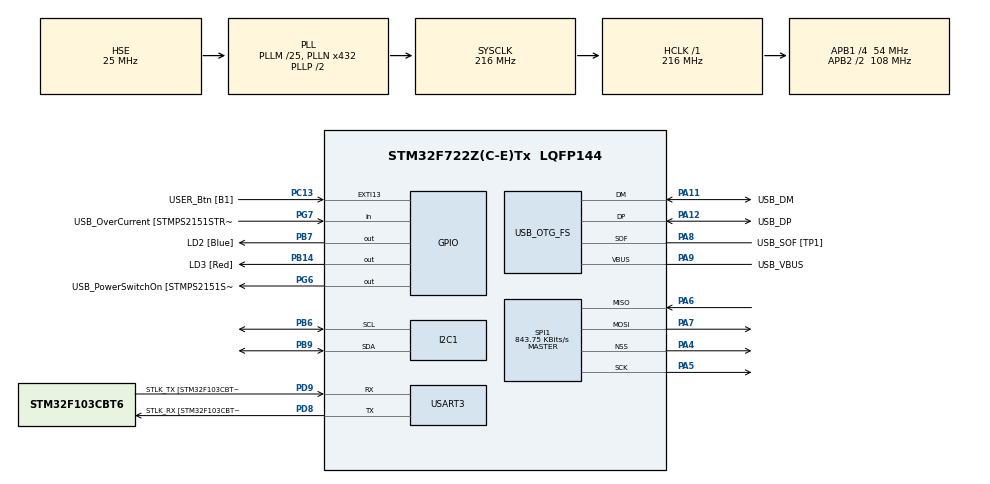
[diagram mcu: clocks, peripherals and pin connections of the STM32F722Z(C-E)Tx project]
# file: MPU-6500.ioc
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Dma.I2C1_RX.1.Direction=DMA_PERIPH_TO_MEMORY
Dma.I2C1_RX.1.FIFOMode=DMA_FIFOMODE_DISABLE
Dma.I2C1_RX.1.Instance=DMA1_Stream0
Dma.I2C1_RX.1.MemDataAlignment=DMA_MDATAALIGN_BYTE
Dma.I2C1_RX.1.MemInc=DMA_MINC_ENABLE
Dma.I2C1_RX.1.Mode=DMA_CIRCULAR
Dma.I2C1_RX.1.PeriphDataAlignment=DMA_PDATAALIGN_BYTE
Dma.I2C1_RX.1.PeriphInc=DMA_PINC_DISABLE
Dma.I2C1_RX.1.Priority=DMA_PRIORITY_MEDIUM
Dma.I2C1_TX.0.Direction=DMA_MEMORY_TO_PERIPH
Dma.I2C1_TX.0.FIFOMode=DMA_FIFOMODE_DISABLE
Dma.I2C1_TX.0.Instance=DMA1_Stream6
Dma.I2C1_TX.0.MemDataAlignment=DMA_MDATAALIGN_BYTE
Dma.I2C1_TX.0.MemInc=DMA_MINC_ENABLE
Dma.I2C1_TX.0.Mode=DMA_CIRCULAR
Dma.I2C1_TX.0.PeriphDataAlignment=DMA_PDATAALIGN_BYTE
Dma.I2C1_TX.0.PeriphInc=DMA_PINC_DISABLE
Dma.I2C1_TX.0.Priority=DMA_PRIORITY_MEDIUM
Dma.Request0=I2C1_TX
Dma.Request1=I2C1_RX
Dma.Request2=SPI1_RX
Dma.Request3=SPI1_TX
Dma.SPI1_RX.2.Direction=DMA_PERIPH_TO_MEMORY
Dma.SPI1_RX.2.FIFOMode=DMA_FIFOMODE_DISABLE
Dma.SPI1_RX.2.Instance=DMA2_Stream0
Dma.SPI1_RX.2.MemDataAlignment=DMA_MDATAALIGN_BYTE
Dma.SPI1_RX.2.MemInc=DMA_MINC_ENABLE
Dma.SPI1_RX.2.Mode=DMA_NORMAL
Dma.SPI1_RX.2.PeriphDataAlignment=DMA_PDATAALIGN_BYTE
Dma.SPI1_RX.2.PeriphInc=DMA_PINC_DISABLE
Dma.SPI1_RX.2.Priority=DMA_PRIORITY_HIGH
Dma.SPI1_TX.3.Direction=DMA_MEMORY_TO_PERIPH
Dma.SPI1_TX.3.FIFOMode=DMA_FIFOMODE_DISABLE
Dma.SPI1_TX.3.Instance=DMA2_Stream3
Dma.SPI1_TX.3.MemDataAlignment=DMA_MDATAALIGN_BYTE
Dma.SPI1_TX.3.MemInc=DMA_MINC_ENABLE
Dma.SPI1_TX.3.Mode=DMA_NORMAL
Dma.SPI1_TX.3.PeriphDataAlignment=DMA_PDATAALIGN_BYTE
Dma.SPI1_TX.3.PeriphInc=DMA_PINC_DISABLE
Dma.SPI1_TX.3.Priority=DMA_PRIORITY_HIGH
I2C1.Timing=0x20404768
Mcu.Family=STM32F7
Mcu.Name=STM32F722Z(C-E)Tx
Mcu.Package=LQFP144
NVIC.DMA1_Stream0_IRQn=true\:0\:0\:false\:false\:true\:false\:true
NVIC.DMA1_Stream6_IRQn=true\:0\:0\:false\:false\:true\:false\:true
NVIC.DMA2_Stream0_IRQn=true\:0\:0\:false\:false\:true\:false\:true
NVIC.DMA2_Stream3_IRQn=true\:0\:0\:false\:false\:true\:false\:true
NVIC.PriorityGroup=NVIC_PRIORITYGROUP_4
NVIC.SPI1_IRQn=true\:0\:0\:false\:false\:true\:true\:true
PA10.GPIO_Label=USB_ID
PA10.Signal=USB_OTG_FS_ID
PA11.GPIO_Label=USB_DM
PA11.Mode=Device_Only
PA11.Signal=USB_OTG_FS_DM
PA12.GPIO_Label=USB_DP
PA12.Mode=Device_Only
PA12.Signal=USB_OTG_FS_DP
PA13.GPIO_Label=TMS
PA13.Mode=Serial_Wire
PA13.Signal=SYS_JTMS-SWDIO
PA14.GPIO_Label=TCK
PA14.Mode=Serial_Wire
PA14.Signal=SYS_JTCK-SWCLK
PA4.Mode=NSS_Signal_Hard_Output
PA4.Signal=SPI1_NSS
PA5.Mode=Full_Duplex_Master
PA5.Signal=SPI1_SCK
PA6.Mode=Full_Duplex_Master
PA6.Signal=SPI1_MISO
PA7.Mode=Full_Duplex_Master
PA7.Signal=SPI1_MOSI
PA8.GPIO_Label=USB_SOF [TP1]
PA8.Mode=Activate_SOF_FS
PA8.Signal=USB_OTG_FS_SOF
PA9.GPIO_Label=USB_VBUS
PA9.Mode=Activate_VBUS
PA9.Signal=USB_OTG_FS_VBUS
PB14.GPIO_Label=LD3 [Red]
PB14.Signal=GPIO_Output
PB3.GPIO_Label=SWO
PB3.Signal=SYS_JTDO-SWO
PB6.Mode=I2C
PB6.Signal=I2C1_SCL
PB7.GPIO_Label=LD2 [Blue]
PB7.Signal=GPIO_Output
PB9.Mode=I2C
PB9.Signal=I2C1_SDA
PC13.GPIO_Label=USER_Btn [B1]
PC13.Signal=GPXTI13
PC14-OSC32_IN.Mode=LSE-External-Oscillator
PC14-OSC32_IN.Signal=RCC_OSC32_IN
PC15-OSC32_OUT.Mode=LSE-External-Oscillator
PC15-OSC32_OUT.Signal=RCC_OSC32_OUT
PD8.GPIO_Label=STLK_RX [STM32F103CBT6_PA3]
PD8.Mode=Asynchronous
PD8.Signal=USART3_TX
PD9.GPIO_Label=STLK_TX [STM32F103CBT6_PA2]
PD9.Mode=Asynchronous
PD9.Signal=USART3_RX
PG6.GPIO_Label=USB_PowerSwitchOn [STMPS2151STR_EN]
PG6.Signal=GPIO_Output
PG7.GPIO_Label=USB_OverCurrent [STMPS2151STR_FAULT]
PG7.Signal=GPIO_Input
PH0-OSC_IN.GPIO_Label=MCO
PH0-OSC_IN.Mode=HSE-External-Clock-Source
PH0-OSC_IN.Signal=RCC_OSC_IN
PH1-OSC_OUT.Mode=HSE-External-Clock-Source
PH1-OSC_OUT.Signal=RCC_OSC_OUT
ProjectManager.HeapSize=0x2000
ProjectManager.StackSize=0x4000
ProjectManager.TargetToolchain=STM32CubeIDE
RCC.48MHZClocksFreq_Value=24000000
RCC.AHBFreq_Value=216000000
RCC.APB1CLKDivider=RCC_HCLK_DIV4
RCC.APB1Freq_Value=54000000
RCC.APB1TimFreq_Value=108000000
RCC.APB2CLKDivider=RCC_HCLK_DIV2
RCC.APB2Freq_Value=108000000
RCC.APB2TimFreq_Value=216000000
RCC.CortexFreq_Value=216000000
RCC.HCLKFreq_Value=216000000
RCC.HSE_VALUE=25000000
RCC.HSI_VALUE=16000000
RCC.PLLM=25
RCC.PLLMUL=RCC_PLL_MUL9
RCC.PLLN=432
RCC.PLLQ=9
RCC.PRESCALERUSB=RCC_USBCLKSOURCE_PLL_DIV1_5
RCC.SYSCLKFreq_VALUE=216000000
RCC.SYSCLKSource=RCC_SYSCLKSOURCE_PLLCLK
RCC.SYSCLKSourceVirtual=RCC_SYSCLKSOURCE_PLLCLK
RCC.USBFreq_Value=48000000
RCC.VCOOutputFreq_Value=432000000
SPI1.BaudRatePrescaler=SPI_BAUDRATEPRESCALER_128
SPI1.CalculateBaudRate=843.75 KBits/s
SPI1.DataSize=SPI_DATASIZE_8BIT
SPI1.Direction=SPI_DIRECTION_2LINES
SPI1.Mode=SPI_MODE_MASTER
SPI1.NSSPMode=SPI_NSS_PULSE_ENABLE
SPI1.VirtualNSS=VM_NSSHARD
SPI1.VirtualType=VM_MASTER
USART3.VirtualMode-Asynchronous=VM_ASYNC
USB_OTG_FS.VirtualMode=Device_Only
board=NUCLEO-F722ZE

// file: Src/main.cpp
/* USER CODE BEGIN Header */
/**
  ******************************************************************************
  * @file           : main.c
  * @brief          : Main program body
  ******************************************************************************
  * @attention
  *
  * <h2><center>&copy; Copyright (c) 2019 STMicroelectronics.
  * All rights reserved.</center></h2>
  *
  * This software component is licensed by ST under BSD 3-Clause license,
  * the "License"; You may not use this file except in compliance with the
  * License. You may obtain a copy of the License at:
  *                        opensource.org/licenses/BSD-3-Clause
  *
  ******************************************************************************
  */
/* USER CODE END Header */

#include "main.h"
#include "dma.h"
#include "i2c.h"
#include "spi.h"
#include "usart.h"
#include "usb_otg.h"
#include "gpio.h"
#include "MPU6500.h"
#include <string.h>

void SystemClock_Config(void);

/* USER CODE BEGIN 0 */
Sensor::MPU6500 mpu65;
/* USER CODE END 0 */

int main(void)
{

  /* MCU Configuration--------------------------------------------------------*/

  /* Reset of all peripherals, Initializes the Flash interface and the Systick. */
  HAL_Init();

  /* Configure the system clock */
  SystemClock_Config();

  /* Initialize all configured peripherals */
  MX_GPIO_Init();
  MX_DMA_Init();
  MX_SPI1_Init();
  MX_USART3_UART_Init();
  MX_I2C1_Init();
  MX_USB_OTG_FS_PCD_Init();
  /* USER CODE BEGIN 2 */
  HAL_GPIO_WritePin(GPIOA,GPIO_PIN_4,GPIO_PIN_SET);
  mpu65.Initalize();
  /* USER CODE END 2 */
  /* Infinite loop */
  while (1)
  {
	 /* HAL_SPI_Init(&hspi1);
	  HAL_SPI_Transmit(&hspi1, (uint8_t *)message, strlen(message), HAL_MAX_DELAY);
	 HAL_SPI_DeInit(&hspi1);*/
	  mpu65.ReadAccel();

	  HAL_Delay(500);

  }
}
  /* USER CODE END 3 */

void SystemClock_Config(void)
{
  RCC_OscInitTypeDef RCC_OscInitStruct = {0};
  RCC_ClkInitTypeDef RCC_ClkInitStruct = {0};
  RCC_PeriphCLKInitTypeDef PeriphClkInitStruct = {0};

  /** Configure LSE Drive Capability
  */
  HAL_PWR_EnableBkUpAccess();
  /** Configure the main internal regulator output voltage
  */
  __HAL_RCC_PWR_CLK_ENABLE();
  __HAL_PWR_VOLTAGESCALING_CONFIG(PWR_REGULATOR_VOLTAGE_SCALE1);
  /** Initializes the CPU, AHB and APB busses clocks
  */
  RCC_OscInitStruct.OscillatorType = RCC_OSCILLATORTYPE_HSE;
  RCC_OscInitStruct.HSEState = RCC_HSE_BYPASS;
  RCC_OscInitStruct.PLL.PLLState = RCC_PLL_ON;
  RCC_OscInitStruct.PLL.PLLSource = RCC_PLLSOURCE_HSE;
  RCC_OscInitStruct.PLL.PLLM = 25;
  RCC_OscInitStruct.PLL.PLLN = 432;
  RCC_OscInitStruct.PLL.PLLP = RCC_PLLP_DIV2;
  RCC_OscInitStruct.PLL.PLLQ = 9;
  if (HAL_RCC_OscConfig(&RCC_OscInitStruct) != HAL_OK)
  {
    Error_Handler();
  }
  /** Activate the Over-Drive mode
  */
  if (HAL_PWREx_EnableOverDrive() != HAL_OK)
  {
    Error_Handler();
  }
  /** Initializes the CPU, AHB and APB busses clocks
  */
  RCC_ClkInitStruct.ClockType = RCC_CLOCKTYPE_HCLK|RCC_CLOCKTYPE_SYSCLK
                              |RCC_CLOCKTYPE_PCLK1|RCC_CLOCKTYPE_PCLK2;
  RCC_ClkInitStruct.SYSCLKSource = RCC_SYSCLKSOURCE_PLLCLK;
  RCC_ClkInitStruct.AHBCLKDivider = RCC_SYSCLK_DIV1;
  RCC_ClkInitStruct.APB1CLKDivider = RCC_HCLK_DIV4;
  RCC_ClkInitStruct.APB2CLKDivider = RCC_HCLK_DIV2;

  if (HAL_RCC_ClockConfig(&RCC_ClkInitStruct, FLASH_LATENCY_7) != HAL_OK)
  {
    Error_Handler();
  }
  PeriphClkInitStruct.PeriphClockSelection = RCC_PERIPHCLK_USART3|RCC_PERIPHCLK_I2C1
                              |RCC_PERIPHCLK_CLK48;
  PeriphClkInitStruct.Usart3ClockSelection = RCC_USART3CLKSOURCE_PCLK1;
  PeriphClkInitStruct.I2c1ClockSelection = RCC_I2C1CLKSOURCE_PCLK1;
  PeriphClkInitStruct.Clk48ClockSelection = RCC_CLK48SOURCE_PLL;
  if (HAL_RCCEx_PeriphCLKConfig(&PeriphClkInitStruct) != HAL_OK)
  {
    Error_Handler();
  }
}

void Error_Handler(void)
{
}

/************************ (C) COPYRIGHT STMicroelectronics *****END OF FILE****/
